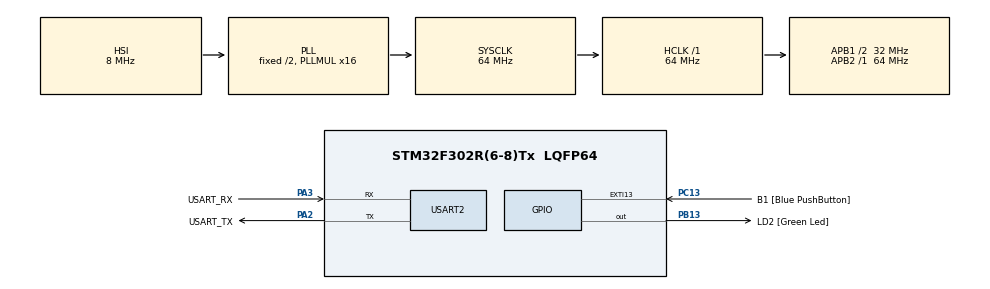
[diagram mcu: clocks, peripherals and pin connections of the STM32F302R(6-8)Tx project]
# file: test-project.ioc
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Mcu.Family=STM32F3
PA2.GPIO_PuPd=GPIO_NOPULL
RCC.CortexFreq_Value=64000000
PC13.Signal=GPXTI13
PA14.GPIO_Label=TCK
RCC.SYSCLKSourceVirtual=RCC_SYSCLKSOURCE_PLLCLK
PA3.GPIO_PuPd=GPIO_NOPULL
PA2.GPIO_Speed=GPIO_SPEED_FREQ_LOW
PC13.GPIO_Label=B1 [Blue PushButton]
RCC.APB1CLKDivider=RCC_HCLK_DIV2
PB13.GPIO_Label=LD2 [Green Led]
PA3.GPIO_Speed=GPIO_SPEED_FREQ_LOW
PB13.Signal=GPIO_Output
ProjectManager.StackSize=0x400
PA13.Signal=SYS_JTMS-SWDIO
PA3.Mode=Asynchronous
PC14\ -\ OSC32_IN.Mode=LSE-External-Oscillator
ProjectManager.TargetToolchain=Makefile
PA3.GPIO_Mode=GPIO_MODE_AF_PP
RCC.HCLKFreq_Value=64000000
RCC.APB2TimFreq_Value=64000000
RCC.USBFreq_Value=64000000
RCC.AHBFreq_Value=64000000
PF0-OSC_IN.Mode=HSE-External-Clock-Source
PC15\ -\ OSC32_OUT.Signal=RCC_OSC32_OUT
RCC.HSE_VALUE=8000000
PB3.Mode=Trace_Asynchronous_SW
board=NUCLEO-F302R8
USART2.VirtualMode-Asynchronous=VM_ASYNC
RCC.RCC_PLLsource_Clock_Source_FROM_HSE=RCC_HSE_PREDIV_DIV2
RCC.PLLMUL=RCC_PLL_MUL16
RCC.APB2Freq_Value=64000000
PA14.Mode=Serial_Wire
PA13.Mode=Serial_Wire
Mcu.Name=STM32F302R(6-8)Tx
PA2.Signal=USART2_TX
PA13.GPIO_Label=TMS
PB3.Signal=SYS_JTDO-TRACESWO
RCC.SYSCLKFreq_VALUE=64000000
Mcu.Package=LQFP64
PC13.GPIO_ModeDefaultEXTI=GPIO_MODE_IT_FALLING
PA2.GPIO_Label=USART_TX
PA14.Signal=SYS_JTCK-SWCLK
PC15\ -\ OSC32_OUT.Mode=LSE-External-Oscillator
ProjectManager.HeapSize=0x200
RCC.HSI_VALUE=8000000
RCC.PLLP=RCC_PLLP_DIV4
RCC.PLLQ=7
NVIC.PriorityGroup=NVIC_PRIORITYGROUP_0
RCC.PLLM=8
RCC.PLLN=336
RCC.APB1TimFreq_Value=64000000
PA2.Mode=Asynchronous
PF0-OSC_IN.Signal=RCC_OSC_IN
RCC.APB1Freq_Value=32000000
PF1-OSC_OUT.Signal=RCC_OSC_OUT
PA3.GPIO_Label=USART_RX
PA3.Signal=USART2_RX
PC14\ -\ OSC32_IN.Signal=RCC_OSC32_IN
PA2.GPIO_Mode=GPIO_MODE_AF_PP
PB3.GPIO_Label=SWO

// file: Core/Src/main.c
/* USER CODE BEGIN Header */
/**
  ******************************************************************************
  * @file           : main.c
  * @brief          : Main program body
  ******************************************************************************
  * @attention
  *
  * <h2><center>&copy; Copyright (c) 2020 STMicroelectronics.
  * All rights reserved.</center></h2>
  *
  * This software component is licensed by ST under BSD 3-Clause license,
  * the "License"; You may not use this file except in compliance with the
  * License. You may obtain a copy of the License at:
  *                        opensource.org/licenses/BSD-3-Clause
  *
  ******************************************************************************
  */
/* USER CODE END Header */
#include "main.h"
#include "usart.h"
#include "gpio.h"

void SystemClock_Config(void);

int main(void)
{

  /* MCU Configuration--------------------------------------------------------*/

  /* Reset of all peripherals, Initializes the Flash interface and the Systick. */
  HAL_Init();

  /* Configure the system clock */
  SystemClock_Config();

  /* Initialize all configured peripherals */
  MX_GPIO_Init();
  MX_USART2_UART_Init();

  /* Infinite loop */
  while (1)
  {
    HAL_GPIO_WritePin(LD2_GPIO_Port, LD2_Pin, GPIO_PIN_SET);
    HAL_Delay(1000);
    HAL_GPIO_WritePin(LD2_GPIO_Port, LD2_Pin, GPIO_PIN_RESET);
    HAL_Delay(1000);

    // how to see print statements?

  }
}

void SystemClock_Config(void)
{
  RCC_OscInitTypeDef RCC_OscInitStruct = {0};
  RCC_ClkInitTypeDef RCC_ClkInitStruct = {0};

  /** Initializes the RCC Oscillators according to the specified parameters
  * in the RCC_OscInitTypeDef structure.
  */
  RCC_OscInitStruct.OscillatorType = RCC_OSCILLATORTYPE_HSI;
  RCC_OscInitStruct.HSIState = RCC_HSI_ON;
  RCC_OscInitStruct.HSICalibrationValue = RCC_HSICALIBRATION_DEFAULT;
  RCC_OscInitStruct.PLL.PLLState = RCC_PLL_ON;
  RCC_OscInitStruct.PLL.PLLSource = RCC_PLLSOURCE_HSI;
  RCC_OscInitStruct.PLL.PLLMUL = RCC_PLL_MUL16;
  if (HAL_RCC_OscConfig(&RCC_OscInitStruct) != HAL_OK)
  {
    Error_Handler();
  }
  /** Initializes the CPU, AHB and APB buses clocks
  */
  RCC_ClkInitStruct.ClockType = RCC_CLOCKTYPE_HCLK|RCC_CLOCKTYPE_SYSCLK
                              |RCC_CLOCKTYPE_PCLK1|RCC_CLOCKTYPE_PCLK2;
  RCC_ClkInitStruct.SYSCLKSource = RCC_SYSCLKSOURCE_PLLCLK;
  RCC_ClkInitStruct.AHBCLKDivider = RCC_SYSCLK_DIV1;
  RCC_ClkInitStruct.APB1CLKDivider = RCC_HCLK_DIV2;
  RCC_ClkInitStruct.APB2CLKDivider = RCC_HCLK_DIV1;

  if (HAL_RCC_ClockConfig(&RCC_ClkInitStruct, FLASH_LATENCY_2) != HAL_OK)
  {
    Error_Handler();
  }
}

/* USER CODE BEGIN 4 */

void blink(uint32_t on, uint32_t off) {
  // HAL_GPIO_WritePin(LD2_GPIO_Port, LD2_Pin, GPIO_PIN_SET);
  // HAL_Delay(on);
  // HAL_GPIO_WritePin(LD2_GPIO_Port, LD2_Pin, GPIO_PIN_RESET);
  // HAL_Delay(off);

  HAL_GPIO_TogglePin(LD2_GPIO_Port, LD2_Pin);
  HAL_Delay(750);
}
/* USER CODE END 4 */

void Error_Handler(void)
{
}

/************************ (C) COPYRIGHT STMicroelectronics *****END OF FILE****/
